# NM1500_v1 register map
File version: 1.0
Registers are 32-bit, read-write, reset 0x0 unless marked. A register's access mark holds for its fields unless they carry their own. Offsets are from the block's base; [hi:lo] are bit positions; {n}, {i} and the like mark numbered series.

## CAP1 — CAP Register Map
Base 0x401B4000
0x00 CAP_CNT — Input Capture Counter (24-bit up counter)
  [23:0] CAP_CNT — Input Capture Timer/Counter. The input Capture Timer/Counter is a 24-bit up-counting counter. The clock source for the counter is from the clock divider output which the CAP_CLK is software optionally divided by 1,4,16 or 32.
{0x4+4i} CAP_HLD{i} (i=0..2) — Input Capture Counter Hold Register 0
  [23:0] CAP_HLD — Input Capture Counter Hold Register. When an active input capture channel detects a valid edge signal change, the CAPCNT value is latched into the corresponding holding register. Each input channel has itself holding register named by CAP_HLDx where x is from 0 to 2 to indicate inputs from IC0 to IC2, respectively.
0x10 CAP_CNTCMP — Input Capture Counter Compare Register
  [23:0] CAP_CNTCMP
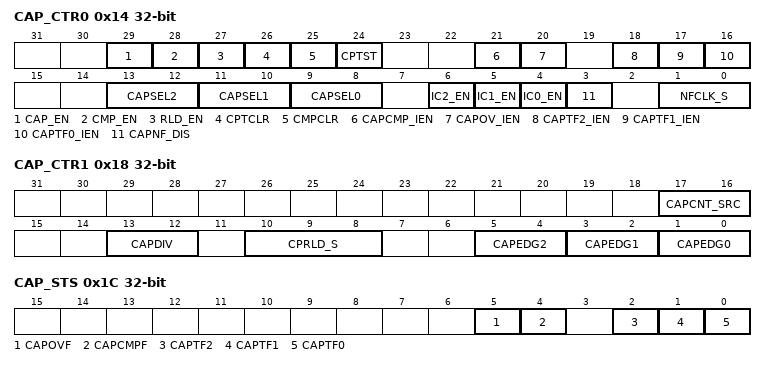
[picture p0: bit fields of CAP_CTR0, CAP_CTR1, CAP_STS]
0x14 CAP_CTR0 — Input Capture Control Register 0
  [29] CAP_EN — Input Capture Timer/Counter Enable Bit
    0=Input Capture function Disabled; 1=Input Capture function Enabled
  [28] CMP_EN — The Compare Function Enable Bit. The compare function in input capture timer/counter is to compare the dynamic counting CAP_CNT with the compare register CAP_CNTCMP, if CAP_CNT value reaches CAP_CNTCMP, the flag CAPCMPF will be set.
    0=Compare function Disabled; 1=Compare function Enabled
  [27] RLD_EN — The Reload Function Enable Bit. Setting this bit to enable reload function. If the reload control is enabled, an overflow event (CAPOVF) or capture events (CAPTFx) will trigger the hardware to reload CAP_CNTCMP into CAP_CNT.
    0=Reload function Disabled; 1=Reload function Enabled
  [26] CPTCLR — Input Capture Counter Clear by Capture Events Control Bit. If this bit is set to 1, the capture counter (CAP_CNT) will be cleared to 0 when any one of capture events (CAPTF0~3) occurs.
    0=Capture events (CAPTF0~3) can clear capture counter (CAP_CNT) Disabled; 1=Capture events (CAPTF0~3) can clear capture counter (CAP_CNT) Enabled
  [25] CMPCLR — Input Capture Counter Clear by Compare-match Control Bit
    0=Compare-match event (CAMCMPF) can clear capture counter (CAP_CNT) Disabled; 1=Compare-match event (CAMCMPF) can clear capture counter (CAP_CNT) Enabled
  [24] CPTST — Input Capture Counter Start Bit. Setting this bit to 1, the capture counter (CAP_CNT) starts up-counting synchronously with capture clock input (CAP_CLK).
    0=CAP_CNT stop counting; 1=CAP_CNT starts up-counting
  [21] CAPCMP_IEN — Enable CAPCMPF Trigger Input Capture Interrupt
    0=Disabling flag CAPCMPF can trigger Input Capture interrupt; 1=Enabling flag CAPCMPF can trigger Input Capture interrupt
  [20] CAPOV_IEN — Enable CAPOVF Trigger Input Capture Interrupt
    0=Disabling flag OVUNF can trigger Input Capture interrupt; 1=Enabling flag OVUNF can trigger Input Capture interrupt
  [18] CAPTF2_IEN — Enable Input Capture Channel 2 Interrupt
    0=Disabling flag CAPTF2 can trigger Input Capture interrupt; 1=Enabling flag CAPTF2 can trigger Input Capture interrupt
  [17] CAPTF1_IEN — Enable Input Capture Channel 1 Interrupt
    0=Disabling flag CAPTF1 can trigger Input Capture interrupt; 1=Enabling flag CAPTF1 can trigger Input Capture interrupt
  [16] CAPTF0_IEN — Enable Input Capture Channel 0 Interrupt
    0=Disabling flag CAPTF0 can trigger Input Capture interrupt; 1=Enabling flag CAPTF0 can trigger Input Capture interrupt
  [13:12] CAPSEL2 — CAP2 Input Source Selection Bit
    0=CAP2 input is from port pin IC2; 1=CAP2 input is from signal CPO2 (Analog comparator 2 output); 2=CAP2 input is from signal CHX of QEI controller unit x; 3=CAP2 input is from signal ADCMPOx (ADC compare output x)
  [11:10] CAPSEL1 — CAP1 Input Source Selection Bit
    0=CAP1 input is from port pin IC1; 1=CAP1 input is from signal CPO1 (Analog comparator 1 output); 2=CAP1 input is from signal CHB of QEI controller unit x; 3=CAP1 input is from signal OPDO1 (OP1 digital output)
  [9:8] CAPSEL0 — CAP0 Input Source Selection Bit
    0=CAP0 input is from port pin IC0; 1=CAP0 input is from signal CPO0 (Analog comparator 0 output); 2=CAP0 input is from signal CHA of QEI controller unit x; 3=CAP0 input is from signal OPDO0 (OP0 digital output)
  [6] IC2_EN — Enable Port Pin IC2 Input to Input Capture Unit
    0=IC2 input to Input Capture Unit Disabled; 1=IC2 input to Input Capture Unit Enabled
  [5] IC1_EN — Enable Port Pin IC1 Input to Input Capture Unit
    0=IC1 input to Input Capture Unit Disabled; 1=IC1 input to Input Capture Unit Enabled
  [4] IC0_EN — Enable Port Pin IC0 Input to Input Capture Unit
    0=IC0 input to Input Capture Unit Disabled; 1=IC0 input to Input Capture Unit Enabled
  [3] CAPNF_DIS — Disable Input Capture Noise Filter
    0=Noise filter of Input Capture Enabled; 1=The noise filter of Input Capture Disabled
  [1:0] NFCLK_S — Noise Filter Clock Pre-divided Selection
0x18 CAP_CTR1 — Input Capture Control Register 1
  [17:16] CAPCNT_SRC — Capture Timer/Counter Clock Source Select
  [13:12] CAPDIV — Capture Timer Clock Divide Selection
  [10:8] CPRLD_S — CAPCNT Reload Trigger Source Selection
  [5:4] CAPEDG2 — Channel 2 Captured Edge Selection
  [3:2] CAPEDG1 — Channel 1 Captured Edge Selection
  [1:0] CAPEDG0 — Channel 0 Captured Edge Selection
0x1C CAP_STS — Input Capture Status Register
  [5] CAPOVF — Input Capture Counter Overflow Flag. Flag is set by hardware when input capture up counter (CAP_CNT) overflows from 0x00FF_FFFF to 0. Note: This bit is only cleared by writing 1 to itself through software.
    0=No overflow occurs in CAP_CNT; 1=CAP_CNT overflows
  [4] CAPCMPF — Input Capture Compare-match Flag. If the input capture compare function is enabled, the flag is set by hardware while capture counter (CAP_CNT) up counts and reach to the CAP_CNTCMP value. Note: This bit is only cleared by writing 1 to itself through software.
    0=CAP_CNT does not match with CAP_CNTCMP value; 1=CAP_CNT counts to the same as CAP_CNTCMP value
  [2] CAPTF2 — Input Capture Channel 2 Captured Flag. When the input capture channel 2 detects a valid edge change at CAP2 input, it will set flag CAPTF2 to high. Note: This bit is only cleared by writing 1 to itself through software.
    0=No valid edge change is detected at CAP2 input; 1=A valid edge change is detected at CAP2 input
  [1] CAPTF1 — Input Capture Channel 1 Captured Flag. When the input capture channel 1 detects a valid edge change at CAP1 input, it will set flag CAPTF1 to high. Note: This bit is only cleared by writing 1 to itself through software.
    0=No valid edge change is detected at CAP1 input; 1=A valid edge change is detected at CAP1 input
  [0] CAPTF0 — Input Capture Channel 0 Captured Flag. When the input capture channel 0 detects a valid edge change at CAP0 input, it will set flag CAPTF0 to high. Note: This bit is only cleared by writing 1 to itself through software.
    0=No valid edge change is detected at CAP0 input; 1=A valid edge change is detected at CAP0 input
